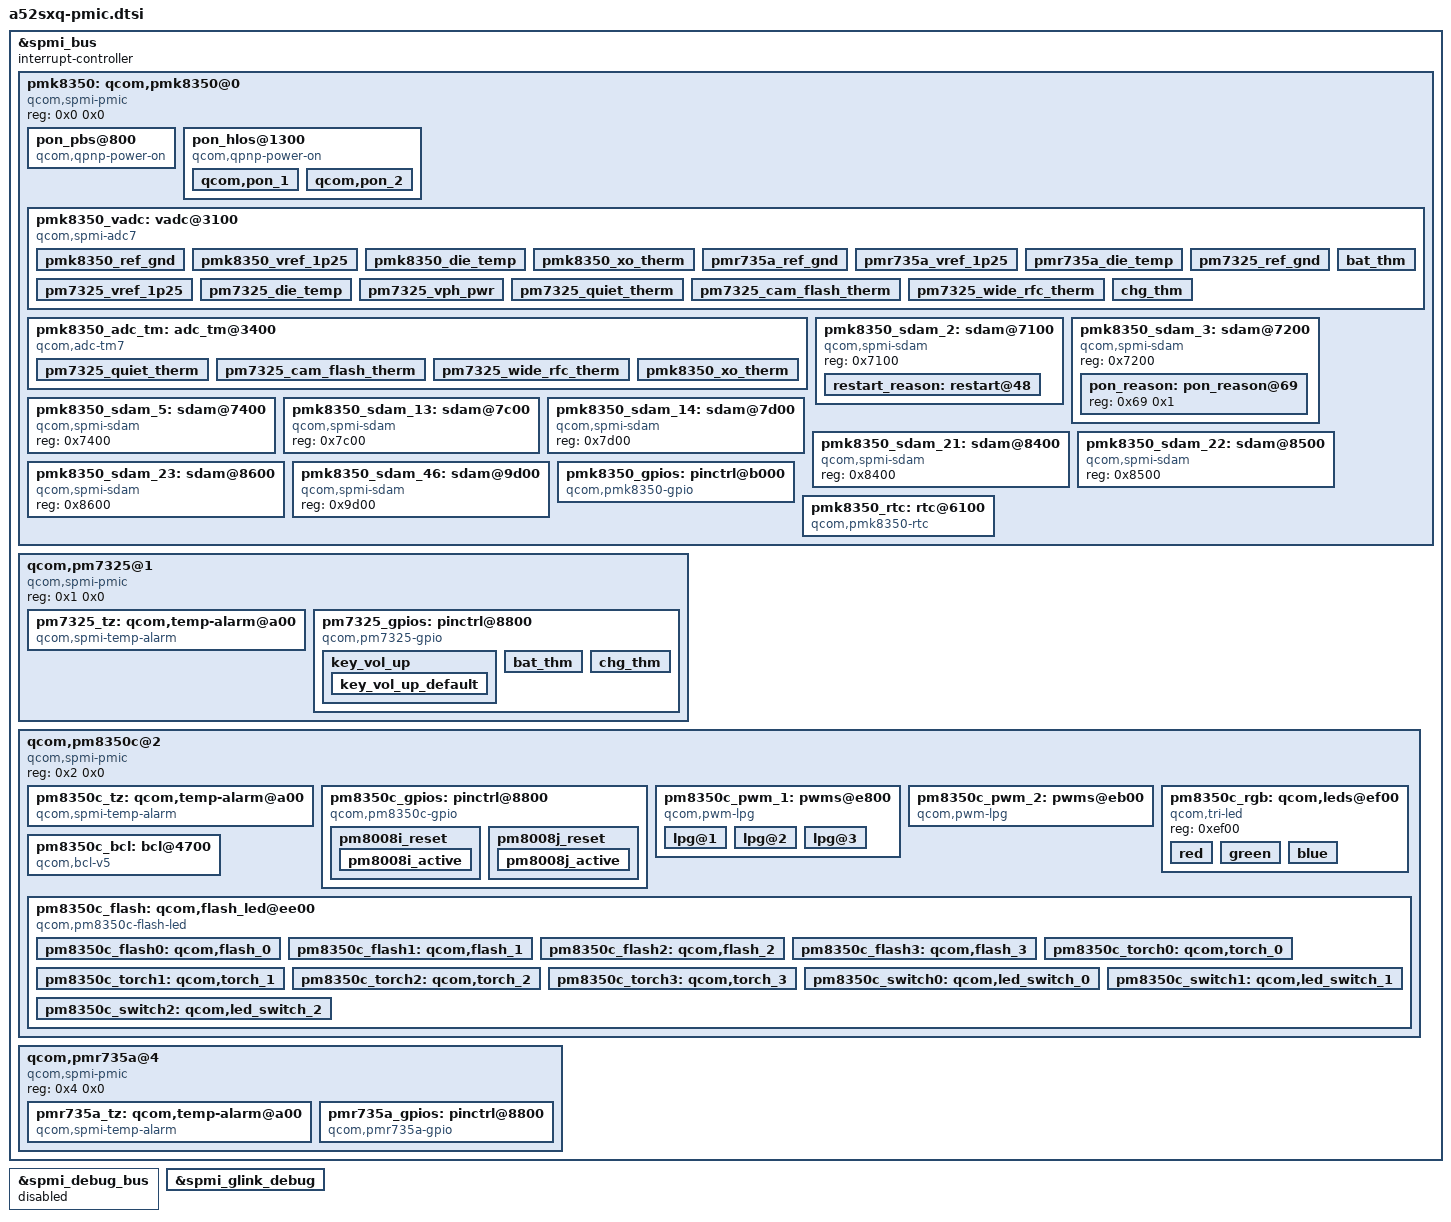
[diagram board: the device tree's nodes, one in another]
// SPDX-License-Identifier: GPL-2.0
/*
 * a52sxq board description for the Qualcomm 6.12 yupik base: pmic
 * GENERATED by tools/gen.py from the phone's stock dtbo (5.4 bindings, values verbatim).
 * Do not edit: hand-written 6.12 changes live in a52sxq-bsp612-fixups.dtsi.
 */

&spmi_bus {
	#address-cells = <0x2>;
	#size-cells = <0x0>;
	interrupt-controller;
	#interrupt-cells = <0x4>;

	pmk8350: qcom,pmk8350@0 {
		compatible = "qcom,spmi-pmic";
		reg = <0x0 0x0>;
		#address-cells = <0x1>;
		#size-cells = <0x0>;

		pon_pbs@800 {
			compatible = "qcom,qpnp-power-on";
			reg = <0x800>;
			qcom,system-reset;
			qcom,store-hard-reset-reason;
		};

		pon_hlos@1300 {
			compatible = "qcom,qpnp-power-on";
			reg = <0x1300 0x800>;
			reg-names = "pon_hlos", "pon_pbs";
			interrupts = <0x0 0x13 0x7 0x3 0x0 0x13 0x6 0x3>;
			interrupt-names = "kpdpwr", "resin";
			qcom,kpdpwr-sw-debounce;

			qcom,pon_1 {
				qcom,pon-type = <0x0>;
				linux,code = <0x74>;
			};

			qcom,pon_2 {
				qcom,pon-type = <0x1>;
				linux,code = <0x72>;
			};
		};

		pmk8350_vadc: vadc@3100 {
			compatible = "qcom,spmi-adc7";
			reg = <0x3100>;
			#address-cells = <0x1>;
			#size-cells = <0x0>;
			interrupts = <0x0 0x31 0x0 0x1>;
			interrupt-names = "eoc-int-en-set";
			#io-channel-cells = <0x1>;
			io-channel-ranges;

			pmk8350_ref_gnd {
				reg = <0x0>;
				label = "pmk8350_ref_gnd";
				qcom,pre-scaling = <0x1 0x1>;
			};

			pmk8350_vref_1p25 {
				reg = <0x1>;
				label = "pmk8350_vref_1p25";
				qcom,pre-scaling = <0x1 0x1>;
			};

			pmk8350_die_temp {
				reg = <0x3>;
				label = "pmk8350_die_temp";
				qcom,pre-scaling = <0x1 0x1>;
			};

			pmk8350_xo_therm {
				reg = <0x44>;
				label = "pmk8350_xo_therm";
				qcom,ratiometric;
				qcom,hw-settle-time = <0xc8>;
				qcom,pre-scaling = <0x1 0x1>;
			};

			pmr735a_ref_gnd {
				reg = <0x400>;
				label = "pmr735a_ref_gnd";
				qcom,pre-scaling = <0x1 0x1>;
			};

			pmr735a_vref_1p25 {
				reg = <0x401>;
				label = "pmr735a_vref_1p25";
				qcom,pre-scaling = <0x1 0x1>;
			};

			pmr735a_die_temp {
				reg = <0x403>;
				label = "pmr735a_die_temp";
				qcom,pre-scaling = <0x1 0x1>;
			};

			pm7325_ref_gnd {
				reg = <0x100>;
				label = "pm7325_ref_gnd";
				qcom,pre-scaling = <0x1 0x1>;
			};

			pm7325_vref_1p25 {
				reg = <0x101>;
				label = "pm7325_vref_1p25";
				qcom,pre-scaling = <0x1 0x1>;
			};

			pm7325_die_temp {
				reg = <0x103>;
				label = "pm7325_die_temp";
				qcom,pre-scaling = <0x1 0x1>;
			};

			pm7325_vph_pwr {
				reg = <0x18e>;
				label = "pm7325_vph_pwr";
				qcom,pre-scaling = <0x1 0x3>;
			};

			pm7325_quiet_therm {
				reg = <0x144>;
				label = "pm7325_quiet_therm";
				qcom,ratiometric;
				qcom,hw-settle-time = <0xc8>;
				qcom,pre-scaling = <0x1 0x1>;
			};

			pm7325_cam_flash_therm {
				reg = <0x145>;
				label = "pm7325_cam_flash_therm";
				qcom,ratiometric;
				qcom,hw-settle-time = <0xc8>;
				qcom,pre-scaling = <0x1 0x1>;
			};

			pm7325_wide_rfc_therm {
				reg = <0x147>;
				label = "pm7325_wide_rfc_therm";
				qcom,ratiometric;
				qcom,hw-settle-time = <0xc8>;
				qcom,pre-scaling = <0x1 0x1>;
			};

			bat_thm {
				label = "bat_thm";
				reg = <0x14b>;
				qcom,pre-scaling = <0x1 0x1>;
				qcom,hw-settle-time = <0xc8>;
				qcom,ratiometric;
				qcom,scale-fn-type = <0x5>;
			};

			chg_thm {
				label = "chg_thm";
				reg = <0x14a>;
				qcom,pre-scaling = <0x1 0x1>;
				qcom,hw-settle-time = <0xc8>;
				qcom,ratiometric;
				qcom,scale-fn-type = <0x5>;
			};
		};

		pmk8350_adc_tm: adc_tm@3400 {
			compatible = "qcom,adc-tm7";
			reg = <0x3400>;
			interrupts = <0x0 0x34 0x0 0x1>;
			interrupt-names = "threshold";
			#address-cells = <0x1>;
			#size-cells = <0x0>;
			#thermal-sensor-cells = <0x1>;
			io-channels = <&pmk8350_vadc 0x144 &pmk8350_vadc 0x145 &pmk8350_vadc 0x146 &pmk8350_vadc 0x147 &pmk8350_vadc 0x44>;

			pm7325_quiet_therm {
				reg = <0x144>;
				qcom,ratiometric;
				qcom,hw-settle-time = <0xc8>;
			};

			pm7325_cam_flash_therm {
				reg = <0x145>;
				qcom,ratiometric;
				qcom,hw-settle-time = <0xc8>;
			};

			pm7325_wide_rfc_therm {
				reg = <0x147>;
				qcom,ratiometric;
				qcom,hw-settle-time = <0xc8>;
			};

			pmk8350_xo_therm {
				reg = <0x44>;
				qcom,ratiometric;
				qcom,hw-settle-time = <0xc8>;
			};
		};

		pmk8350_sdam_2: sdam@7100 {
			compatible = "qcom,spmi-sdam";
			reg = <0x7100>;
			#address-cells = <0x1>;
			#size-cells = <0x1>;

			restart_reason: restart@48 {
				reg = <0x48 0x1>;
				bits = <0x1 0x7>;
			};
		};

		pmk8350_sdam_3: sdam@7200 {
			compatible = "qcom,spmi-sdam";
			reg = <0x7200>;
			#address-cells = <0x1>;
			#size-cells = <0x1>;

			pon_reason: pon_reason@69 {
				reg = <0x69 0x1>;
			};
		};

		pmk8350_sdam_5: sdam@7400 {
			compatible = "qcom,spmi-sdam";
			reg = <0x7400>;
		};

		pmk8350_sdam_13: sdam@7c00 {
			compatible = "qcom,spmi-sdam";
			reg = <0x7c00>;
		};

		pmk8350_sdam_14: sdam@7d00 {
			compatible = "qcom,spmi-sdam";
			reg = <0x7d00>;
		};

		pmk8350_sdam_21: sdam@8400 {
			compatible = "qcom,spmi-sdam";
			reg = <0x8400>;
		};

		pmk8350_sdam_22: sdam@8500 {
			compatible = "qcom,spmi-sdam";
			reg = <0x8500>;
		};

		pmk8350_sdam_23: sdam@8600 {
			compatible = "qcom,spmi-sdam";
			reg = <0x8600>;
			#address-cells = <0x1>;
			#size-cells = <0x1>;
		};

		pmk8350_sdam_46: sdam@9d00 {
			compatible = "qcom,spmi-sdam";
			reg = <0x9d00>;
		};

		pmk8350_gpios: pinctrl@b000 {
			compatible = "qcom,pmk8350-gpio";
			reg = <0xb000>;
			gpio-controller;
			#gpio-cells = <0x2>;
			interrupt-controller;
			#interrupt-cells = <0x2>;
		};

		pmk8350_rtc: rtc@6100 {
			compatible = "qcom,pmk8350-rtc";
			reg = <0x6100 0x6200>;
			reg-names = "rtc", "alarm";
			interrupts = <0x0 0x62 0x1 0x1>;
		};
	};

	qcom,pm7325@1 {
		compatible = "qcom,spmi-pmic";
		reg = <0x1 0x0>;
		#address-cells = <0x1>;
		#size-cells = <0x0>;

		pm7325_tz: qcom,temp-alarm@a00 {
			compatible = "qcom,spmi-temp-alarm";
			reg = <0xa00>;
			interrupts = <0x1 0xa 0x0 0x3>;
			#thermal-sensor-cells = <0x0>;
			io-channels = <&pmk8350_vadc 0x103>;
			io-channel-names = "thermal";
		};

		pm7325_gpios: pinctrl@8800 {
			compatible = "qcom,pm7325-gpio";
			reg = <0x8800>;
			gpio-controller;
			#gpio-cells = <0x2>;
			interrupt-controller;
			#interrupt-cells = <0x2>;

			key_vol_up {

				key_vol_up_default: key_vol_up_default {
					pins = "gpio6";
					function = "normal";
					input-enable;
					bias-pull-up;
					power-source = <0x1>;
				};
			};

			bat_thm {
			};

			chg_thm {
			};
		};
	};

	qcom,pm8350c@2 {
		compatible = "qcom,spmi-pmic";
		reg = <0x2 0x0>;
		#address-cells = <0x1>;
		#size-cells = <0x0>;

		pm8350c_tz: qcom,temp-alarm@a00 {
			compatible = "qcom,spmi-temp-alarm";
			reg = <0xa00>;
			interrupts = <0x2 0xa 0x0 0x3>;
			#thermal-sensor-cells = <0x0>;
		};

		pm8350c_gpios: pinctrl@8800 {
			compatible = "qcom,pm8350c-gpio";
			reg = <0x8800>;
			gpio-controller;
			#gpio-cells = <0x2>;
			interrupt-controller;
			#interrupt-cells = <0x2>;

			pm8008i_reset {

				pm8008i_active: pm8008i_active {
				};
			};

			pm8008j_reset {

				pm8008j_active: pm8008j_active {
				};
			};
		};

		pm8350c_pwm_1: pwms@e800 {
			compatible = "qcom,pwm-lpg";
			reg = <0xe800>;
			reg-names = "lpg-base";
			#pwm-cells = <0x2>;
			qcom,num-lpg-channels = <0x3>;
			nvmem = <&pmk8350_sdam_21 &pmk8350_sdam_22>;
			nvmem-names = "lpg_chan_sdam", "lut_sdam";
			qcom,lut-sdam-base = <0x45>;
			qcom,lut-patterns = <0x0 0xa 0x14 0x1e 0x28 0x32 0x3c 0x46 0x50 0x5a 0x64 0x5a 0x50 0x46 0x3c 0x32 0x28 0x1e 0x14 0xa 0x0>;
			qcom,tick-duration-us = <0x1f40>;

			lpg@1 {
				qcom,lpg-chan-id = <0x1>;
				qcom,ramp-step-ms = <0x64>;
				qcom,ramp-low-index = <0x0>;
				qcom,ramp-high-index = <0x13>;
				qcom,ramp-pattern-repeat;
				qcom,lpg-sdam-base = <0x48>;
			};

			lpg@2 {
				qcom,lpg-chan-id = <0x2>;
				qcom,ramp-step-ms = <0x64>;
				qcom,ramp-low-index = <0x0>;
				qcom,ramp-high-index = <0x13>;
				qcom,ramp-pattern-repeat;
				qcom,lpg-sdam-base = <0x56>;
			};

			lpg@3 {
				qcom,lpg-chan-id = <0x3>;
				qcom,ramp-step-ms = <0x64>;
				qcom,ramp-low-index = <0x0>;
				qcom,ramp-high-index = <0x13>;
				qcom,ramp-pattern-repeat;
				qcom,lpg-sdam-base = <0x64>;
			};
		};

		pm8350c_pwm_2: pwms@eb00 {
			compatible = "qcom,pwm-lpg";
			reg = <0xeb00>;
			reg-names = "lpg-base";
			#pwm-cells = <0x2>;
			qcom,num-lpg-channels = <0x1>;
		};

		pm8350c_rgb: qcom,leds@ef00 {
			compatible = "qcom,tri-led";
			reg = <0xef00>;

			red {
				label = "red";
				pwms = <&pm8350c_pwm_1 0x0 0xf4240>;
				led-sources = <0x0>;
				linux,default-trigger = "timer";
			};

			green {
				label = "green";
				pwms = <&pm8350c_pwm_1 0x1 0xf4240>;
				led-sources = <0x1>;
				linux,default-trigger = "timer";
			};

			blue {
				label = "blue";
				pwms = <&pm8350c_pwm_1 0x2 0xf4240>;
				led-sources = <0x2>;
				linux,default-trigger = "timer";
			};
		};

		pm8350c_bcl: bcl@4700 {
			compatible = "qcom,bcl-v5";
			reg = <0x4700 0x100>;
			interrupts = <0x2 0x47 0x0 0x0 0x2 0x47 0x1 0x0 0x2 0x47 0x2 0x0>;
			interrupt-names = "bcl-lvl0", "bcl-lvl1", "bcl-lvl2";
			qcom,pmic7-threshold;
			#thermal-sensor-cells = <0x1>;
		};

		pm8350c_flash: qcom,flash_led@ee00 {
			compatible = "qcom,pm8350c-flash-led";
			reg = <0xee00>;
			interrupts = <0x2 0xee 0x0 0x1 0x2 0xee 0x3 0x1 0x2 0xee 0x4 0x1>;
			interrupt-names = "led-fault-irq", "all-ramp-down-done-irq", "all-ramp-up-done-irq";
			qcom,thermal-derate-current = <0xc8 0x1f4>;
			qcom,hw-strobe-gpios = <&pm8350c_gpios 0x1 0x0>;
			status = "ok";

			pm8350c_flash0: qcom,flash_0 {
				label = "flash";
				qcom,led-name = "led:flash_0";
				qcom,max-current-ma = <0x5dc>;
				qcom,default-led-trigger = "flash0_trigger";
				qcom,id = <0x0>;
				qcom,duration-ms = <0x500>;
				qcom,ires-ua = <0x30d4>;
			};

			pm8350c_flash1: qcom,flash_1 {
				label = "flash";
				qcom,led-name = "led:flash_1";
				qcom,max-current-ma = <0x5dc>;
				qcom,default-led-trigger = "flash1_trigger";
				qcom,id = <0x1>;
				qcom,duration-ms = <0x500>;
				qcom,ires-ua = <0x30d4>;
			};

			pm8350c_flash2: qcom,flash_2 {
				label = "flash";
				qcom,led-name = "led:flash_2";
				qcom,max-current-ma = <0x5dc>;
				qcom,default-led-trigger = "flash2_trigger";
				qcom,id = <0x2>;
				qcom,duration-ms = <0x500>;
				qcom,ires-ua = <0x30d4>;
			};

			pm8350c_flash3: qcom,flash_3 {
				label = "flash";
				qcom,led-name = "led:flash_3";
				qcom,max-current-ma = <0x5dc>;
				qcom,default-led-trigger = "flash3_trigger";
				qcom,id = <0x3>;
				qcom,duration-ms = <0x500>;
				qcom,ires-ua = <0x30d4>;
			};

			pm8350c_torch0: qcom,torch_0 {
				label = "torch";
				qcom,led-name = "led:torch_0";
				qcom,max-current-ma = <0x1f4>;
				qcom,default-led-trigger = "torch0_trigger";
				qcom,id = <0x0>;
				qcom,ires-ua = <0x30d4>;
			};

			pm8350c_torch1: qcom,torch_1 {
				label = "torch";
				qcom,led-name = "led:torch_1";
				qcom,max-current-ma = <0x1f4>;
				qcom,default-led-trigger = "torch1_trigger";
				qcom,id = <0x1>;
				qcom,ires-ua = <0x30d4>;
			};

			pm8350c_torch2: qcom,torch_2 {
				label = "torch";
				qcom,led-name = "led:torch_2";
				qcom,max-current-ma = <0x1f4>;
				qcom,default-led-trigger = "torch2_trigger";
				qcom,id = <0x2>;
				qcom,ires-ua = <0x30d4>;
			};

			pm8350c_torch3: qcom,torch_3 {
				label = "torch";
				qcom,led-name = "led:torch_3";
				qcom,max-current-ma = <0x1f4>;
				qcom,default-led-trigger = "torch3_trigger";
				qcom,id = <0x3>;
				qcom,ires-ua = <0x30d4>;
			};

			pm8350c_switch0: qcom,led_switch_0 {
				label = "switch";
				qcom,led-name = "led:switch_0";
				qcom,default-led-trigger = "switch0_trigger";
				qcom,led-mask = <0x9>;
				qcom,symmetry-en;
			};

			pm8350c_switch1: qcom,led_switch_1 {
				label = "switch";
				qcom,led-name = "led:switch_1";
				qcom,default-led-trigger = "switch1_trigger";
				qcom,led-mask = <0x6>;
				qcom,symmetry-en;
			};

			pm8350c_switch2: qcom,led_switch_2 {
				label = "switch";
				qcom,led-name = "led:switch_2";
				qcom,default-led-trigger = "switch2_trigger";
				qcom,led-mask = <0xf>;
				qcom,symmetry-en;
			};
		};
	};

	qcom,pmr735a@4 {
		compatible = "qcom,spmi-pmic";
		reg = <0x4 0x0>;
		#address-cells = <0x1>;
		#size-cells = <0x0>;

		pmr735a_tz: qcom,temp-alarm@a00 {
			compatible = "qcom,spmi-temp-alarm";
			reg = <0xa00>;
			interrupts = <0x4 0xa 0x0 0x3>;
			#thermal-sensor-cells = <0x0>;
			io-channels = <&pmk8350_vadc 0x403>;
			io-channel-names = "thermal";
		};

		pmr735a_gpios: pinctrl@8800 {
			compatible = "qcom,pmr735a-gpio";
			reg = <0x8800>;
			gpio-controller;
			#gpio-cells = <0x2>;
			interrupt-controller;
			#interrupt-cells = <0x2>;
		};
	};
};

&spmi_debug_bus {
	status = "disabled";
};

&spmi_glink_debug {
	status = "ok";
};

